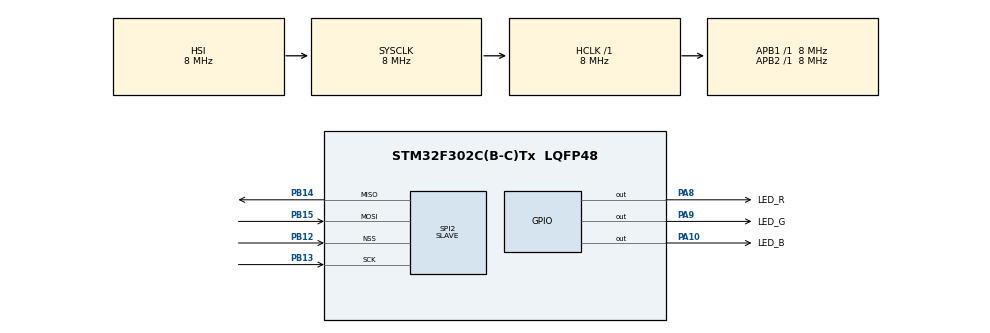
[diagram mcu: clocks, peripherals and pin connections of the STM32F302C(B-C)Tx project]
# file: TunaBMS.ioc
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Mcu.Family=STM32F3
Mcu.Name=STM32F302C(B-C)Tx
Mcu.Package=LQFP48
NVIC.PriorityGroup=NVIC_PRIORITYGROUP_4
PA10.GPIO_Label=LED_B
PA10.GPIO_PuPd=GPIO_PULLDOWN
PA10.Signal=GPIO_Output
PA13.Mode=Trace_Asynchronous_SW
PA13.Signal=SYS_JTMS-SWDIO
PA14.Mode=Trace_Asynchronous_SW
PA14.Signal=SYS_JTCK-SWCLK
PA8.GPIO_Label=LED_R
PA8.GPIO_PuPd=GPIO_PULLDOWN
PA8.Signal=GPIO_Output
PA9.GPIO_Label=LED_G
PA9.GPIO_PuPd=GPIO_PULLDOWN
PA9.Signal=GPIO_Output
PB12.Mode=NSS_Signal_Hard_Input
PB12.Signal=SPI2_NSS
PB13.Mode=Full_Duplex_Slave
PB13.Signal=SPI2_SCK
PB14.Mode=Full_Duplex_Slave
PB14.Signal=SPI2_MISO
PB15.Mode=Full_Duplex_Slave
PB15.Signal=SPI2_MOSI
PB3.Mode=Trace_Asynchronous_SW
PB3.Signal=SYS_JTDO-TRACESWO
PF0-OSC_IN.Mode=HSE-External-Oscillator
PF0-OSC_IN.Signal=RCC_OSC_IN
PF1-OSC_OUT.Mode=HSE-External-Oscillator
PF1-OSC_OUT.Signal=RCC_OSC_OUT
ProjectManager.HeapSize=0x200
ProjectManager.StackSize=0x400
ProjectManager.TargetToolchain=STM32CubeIDE
RCC.AHBFreq_Value=8000000
RCC.APB1Freq_Value=8000000
RCC.APB2Freq_Value=8000000
RCC.CortexFreq_Value=8000000
RCC.HSE_VALUE=8000000
RCC.HSI_VALUE=8000000
RCC.LSE_VALUE=32768
RCC.SYSCLKFreq_VALUE=8000000
SPI2.CLKPhase=SPI_PHASE_2EDGE
SPI2.CLKPolarity=SPI_POLARITY_HIGH
SPI2.DataSize=SPI_DATASIZE_8BIT
SPI2.Direction=SPI_DIRECTION_2LINES
SPI2.Mode=SPI_MODE_SLAVE
SPI2.VirtualNSS=VM_NSSHARD
SPI2.VirtualType=VM_SLAVE
board=custom

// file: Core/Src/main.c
/* USER CODE BEGIN Header */
/**
  ******************************************************************************
  * @file           : main.c
  * @brief          : Main program body
  ******************************************************************************
  * @attention
  *
  * Copyright (c) 2024 STMicroelectronics.
  * All rights reserved.
  *
  * This software is licensed under terms that can be found in the LICENSE file
  * in the root directory of this software component.
  * If no LICENSE file comes with this software, it is provided AS-IS.
  *
  ******************************************************************************
  */
/* USER CODE END Header */
#include "main.h"

SPI_HandleTypeDef hspi2;

void SystemClock_Config(void);
static void MX_GPIO_Init(void);
static void MX_SPI2_Init(void);

int main(void)
{

  /* USER CODE BEGIN 1 */

  uint8_t dataToSend = 2;

  /* USER CODE END 1 */

  /* MCU Configuration--------------------------------------------------------*/

  /* Reset of all peripherals, Initializes the Flash interface and the Systick. */
  HAL_Init();

  /* Configure the system clock */
  SystemClock_Config();

  /* Initialize all configured peripherals */
  MX_GPIO_Init();
  MX_SPI2_Init();
  /* USER CODE BEGIN 2 */

  int input, output = 0;

  /* USER CODE END 2 */

  /* Infinite loop */
  /* USER CODE BEGIN WHILE */
  while (1)
  {
//	  HAL_SPI_Transmit(&hspi2, &dataToSend, 1, HAL_MAX_DELAY);
//	  HAL_Delay(500);

	  HAL_SPI_TransmitReceive(&hspi2, (uint8_t *)&output, (uint8_t*)&input, sizeof(input), HAL_MAX_DELAY);
	  output = input;
    /* USER CODE END WHILE */

  }
}

void SystemClock_Config(void)
{
  RCC_OscInitTypeDef RCC_OscInitStruct = {0};
  RCC_ClkInitTypeDef RCC_ClkInitStruct = {0};

  /** Initializes the RCC Oscillators according to the specified parameters
  * in the RCC_OscInitTypeDef structure.
  */
  RCC_OscInitStruct.OscillatorType = RCC_OSCILLATORTYPE_HSI;
  RCC_OscInitStruct.HSIState = RCC_HSI_ON;
  RCC_OscInitStruct.HSICalibrationValue = RCC_HSICALIBRATION_DEFAULT;
  RCC_OscInitStruct.PLL.PLLState = RCC_PLL_NONE;
  if (HAL_RCC_OscConfig(&RCC_OscInitStruct) != HAL_OK)
  {
    Error_Handler();
  }

  /** Initializes the CPU, AHB and APB buses clocks
  */
  RCC_ClkInitStruct.ClockType = RCC_CLOCKTYPE_HCLK|RCC_CLOCKTYPE_SYSCLK
                              |RCC_CLOCKTYPE_PCLK1|RCC_CLOCKTYPE_PCLK2;
  RCC_ClkInitStruct.SYSCLKSource = RCC_SYSCLKSOURCE_HSI;
  RCC_ClkInitStruct.AHBCLKDivider = RCC_SYSCLK_DIV1;
  RCC_ClkInitStruct.APB1CLKDivider = RCC_HCLK_DIV1;
  RCC_ClkInitStruct.APB2CLKDivider = RCC_HCLK_DIV1;

  if (HAL_RCC_ClockConfig(&RCC_ClkInitStruct, FLASH_LATENCY_0) != HAL_OK)
  {
    Error_Handler();
  }
}

static void MX_SPI2_Init(void)
{

  /* SPI2 parameter configuration*/
  hspi2.Instance = SPI2;
  hspi2.Init.Mode = SPI_MODE_SLAVE;
  hspi2.Init.Direction = SPI_DIRECTION_2LINES;
  hspi2.Init.DataSize = SPI_DATASIZE_8BIT;
  hspi2.Init.CLKPolarity = SPI_POLARITY_HIGH;
  hspi2.Init.CLKPhase = SPI_PHASE_2EDGE;
  hspi2.Init.NSS = SPI_NSS_HARD_INPUT;
  hspi2.Init.FirstBit = SPI_FIRSTBIT_MSB;
  hspi2.Init.TIMode = SPI_TIMODE_DISABLE;
  hspi2.Init.CRCCalculation = SPI_CRCCALCULATION_DISABLE;
  hspi2.Init.CRCPolynomial = 7;
  hspi2.Init.CRCLength = SPI_CRC_LENGTH_DATASIZE;
  hspi2.Init.NSSPMode = SPI_NSS_PULSE_DISABLE;
  if (HAL_SPI_Init(&hspi2) != HAL_OK)
  {
    Error_Handler();
  }

}

static void MX_GPIO_Init(void)
{
  GPIO_InitTypeDef GPIO_InitStruct = {0};

  /* GPIO Ports Clock Enable */
  __HAL_RCC_GPIOF_CLK_ENABLE();
  __HAL_RCC_GPIOB_CLK_ENABLE();
  __HAL_RCC_GPIOA_CLK_ENABLE();

  /*Configure GPIO pin Output Level */
  HAL_GPIO_WritePin(GPIOA, LED_R_Pin|LED_G_Pin|LED_B_Pin, GPIO_PIN_RESET);

  /*Configure GPIO pins : LED_R_Pin LED_G_Pin LED_B_Pin */
  GPIO_InitStruct.Pin = LED_R_Pin|LED_G_Pin|LED_B_Pin;
  GPIO_InitStruct.Mode = GPIO_MODE_OUTPUT_PP;
  GPIO_InitStruct.Pull = GPIO_PULLDOWN;
  GPIO_InitStruct.Speed = GPIO_SPEED_FREQ_LOW;
  HAL_GPIO_Init(GPIOA, &GPIO_InitStruct);

}

void Error_Handler(void)
{
  __disable_irq();
  while (1)
  {
  }
}
